# ATxmega128A1U device description
Architecture: AVR8_XMEGA; Family: AVR XMEGA
Registers are 8-bit, access not given, no defined reset value unless marked. A register's access mark holds for its fields unless they carry their own. Offsets are from the block's base; [hi:lo] are bit positions; lines under a group give offsets from that group; {n}, {i} and the like mark numbered series; 'fields as' and 'values as' point back to an identical list.

## USB_EP_TABLE — USB Endpoint Table
{0x0+0x10*i} EP{i}OUT group (i=0..15) — Endpoint {i}
  0x00 STATUS — Endpoint Status
    [7] STALLF — Endpoint Stall Flag
    [7] CRC — CRC Error Flag
    [6] UNF — Underflow Enpoint FLag
    [6] OVF — Overflow Enpoint Flag for Output Endpoints
    [5] TRNCOMPL0 — Transaction Complete 0 Flag
    [4] TRNCOMPL1 — Transaction Complete 1 Flag
    [4] SETUP — SETUP Transaction Complete Flag
    [3] BANK — Bank Select
    [2] BUSNACK1 — Data Buffer 1 Not Acknowledge
    [1] BUSNACK0 — Data Buffer 0 Not Acknowledge
    [0] TOGGLE — Data Toggle
  0x01 CTRL — Endpoint Control
    [7:6] TYPE — Endpoint Type
      0=DISABLE (Endpoint Disabled); 1=CONTROL; 2=BULK (Bulk/Interrupt); 3=ISOCHRONOUS
    [5] MULTIPKT — Multi Packet Transfer Enable
    [4] PINGPONG — Ping-Pong Enable
    [3] INTDSBL — Interrupt Disable
    [2] STALL — Data Stall
    [2:0] BUFSIZE — Data Buffer Size
      0=8 bytes buffer size; 1=16 bytes buffer size; 2=32 bytes buffer size; 3=64 bytes buffer size; 4=128 bytes buffer size; 5=256 bytes buffer size; 6=512 bytes buffer size; 7=1023 bytes buffer size
  0x02 CNT 16-bit — USB Endpoint Counter
    [15] ZLP — Zero Length Packet
  0x04 DATAPTR 16-bit — Data Pointer
  0x06 AUXDATA 16-bit — Auxiliary Data
{0x8+0x10*i} EP{i}IN group (i=0..15) — Endpoint {i}
  0x00 STATUS — Endpoint Status
    fields as EP0OUT.STATUS
  0x01 CTRL — Endpoint Control
    fields as EP0OUT.CTRL
  0x02 CNT 16-bit — USB Endpoint Counter
    [15] ZLP — Zero Length Packet
  0x04 DATAPTR 16-bit — Data Pointer
  0x06 AUXDATA 16-bit — Auxiliary Data
0x110 FRAMENUML — Frame Number Low Byte
0x111 FRAMENUMH — Frame Number High Byte

## PORT — I/O Ports
Instances: PORTA 0x0600, PORTB 0x0620, PORTC 0x0640, PORTD 0x0660, PORTE 0x0680, PORTF 0x06A0, PORTH 0x06E0, PORTJ 0x0700, PORTK 0x0720, PORTQ 0x07C0, PORTR 0x07E0
0x00 DIR — I/O Port Data Direction
0x01 DIRSET — I/O Port Data Direction Set
0x02 DIRCLR — I/O Port Data Direction Clear
0x03 DIRTGL — I/O Port Data Direction Toggle
0x04 OUT — I/O Port Output
0x05 OUTSET — I/O Port Output Set
0x06 OUTCLR — I/O Port Output Clear
0x07 OUTTGL — I/O Port Output Toggle
0x08 IN — I/O port Input
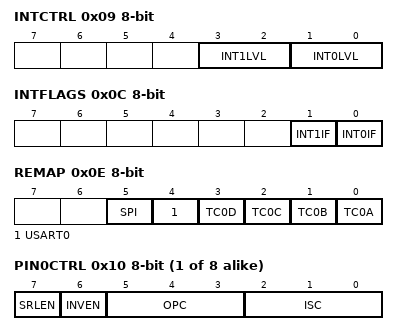
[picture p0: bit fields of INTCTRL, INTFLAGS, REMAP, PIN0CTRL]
0x09 INTCTRL — Interrupt Control Register
  [3:2] INT1LVL — Port Interrupt 1 Level
    0=OFF (Interrupt Disabled); 1=LO (Low Level); 2=MED (Medium Level); 3=HI (High Level)
  [1:0] INT0LVL — Port Interrupt 0 Level
    values as INT1LVL
0x0A INT0MASK — Port Interrupt 0 Mask
0x0B INT1MASK — Port Interrupt 1 Mask
0x0C INTFLAGS — Interrupt Flag Register
  [1] INT1IF — Port Interrupt 1 Flag
  [0] INT0IF — Port Interrupt 0 Flag
0x0E REMAP — I/O Port Pin Remap Register
  [5] SPI
  [4] USART0
  [3] TC0D — Timer/Counter 0 Output Compare D
  [2] TC0C — Timer/Counter 0 Output Compare C
  [1] TC0B — Timer/Counter 0 Output Compare B
  [0] TC0A — Timer/Counter 0 Output Compare A
{0x10+i} PIN{i}CTRL (i=0..7) — Pin {i} Control Register
  [7] SRLEN — Slew Rate Enable
  [6] INVEN — Inverted I/O Enable
  [5:3] OPC — Output/Pull Configuration
    0=TOTEM (Totempole); 1=BUSKEEPER (Totempole w/ Bus keeper on Input and Output); 2=PULLDOWN (Totempole w/ Pull-down on Input); 3=PULLUP (Totempole w/ Pull-up on Input); 4=WIREDOR; 5=WIREDAND; 6=WIREDORPULL (Wired OR w/ Pull-down); 7=WIREDANDPULL (Wired AND w/ Pull-up)
  [2:0] ISC — Input/Sense Configuration
    0=BOTHEDGES (Sense Both Edges); 1=RISING (Sense Rising Edge); 2=FALLING (Sense Falling Edge); 3=LEVEL (Sense Level (Transparent For Events)); 7=INPUT_DISABLE (Disable Digital Input Buffer)

## TC2 — 16-bit Timer/Counter type 2
Instances: TCC2 0x800, TCD2 0x900, TCE2 0xA00, TCF2 0xB00
0x00 CTRLA — Control Register A
  [3:0] CLKSEL — Clock Selection
    0=OFF (Timer Off); 1=DIV1 (System Clock); 2=DIV2 (System Clock / 2); 3=DIV4 (System Clock / 4); 4=DIV8 (System Clock / 8); 5=DIV64 (System Clock / 64); 6=DIV256 (System Clock / 256); 7=DIV1024 (System Clock / 1024); {v}=EVCH{v-8} (Event Channel {v-8}) (v=8..15)
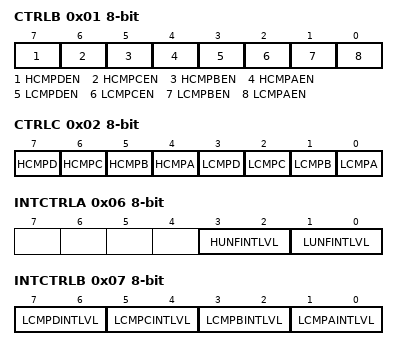
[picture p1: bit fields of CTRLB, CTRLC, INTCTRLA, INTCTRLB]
0x01 CTRLB — Control Register B
  [7] HCMPDEN — High Byte Compare D Enable
  [6] HCMPCEN — High Byte Compare C Enable
  [5] HCMPBEN — High Byte Compare B Enable
  [4] HCMPAEN — High Byte Compare A Enable
  [3] LCMPDEN — Low Byte Compare D Enable
  [2] LCMPCEN — Low Byte Compare C Enable
  [1] LCMPBEN — Low Byte Compare B Enable
  [0] LCMPAEN — Low Byte Compare A Enable
0x02 CTRLC — Control register C
  [7] HCMPD — High Byte Compare D Output Value
  [6] HCMPC — High Byte Compare C Output Value
  [5] HCMPB — High Byte Compare B Output Value
  [4] HCMPA — High Byte Compare A Output Value
  [3] LCMPD — Low Byte Compare D Output Value
  [2] LCMPC — Low Byte Compare C Output Value
  [1] LCMPB — Low Byte Compare B Output Value
  [0] LCMPA — Low Byte Compare A Output Value
0x04 CTRLE — Control Register E
  [1:0] BYTEM — Byte Mode
    0=NORMAL (16-bit mode); 1=BYTEMODE (Timer/Counter operating in byte mode only (TC2)); 2=SPLITMODE (Timer/Counter split into two 8-bit Counters)
0x06 INTCTRLA — Interrupt Control Register A
  [3:2] HUNFINTLVL — High Byte Underflow Interrupt Level
    0=OFF (Interrupt Disabled); 1=LO (Low Level); 2=MED (Medium Level); 3=HI (High Level)
  [1:0] LUNFINTLVL — Low Byte Underflow interrupt level
    values as HUNFINTLVL
0x07 INTCTRLB — Interrupt Control Register B
  [all] fields
    values as INTCTRLA.HUNFINTLVL
  [7:6] LCMPDINTLVL — Low Byte Compare D Interrupt Level
  [5:4] LCMPCINTLVL — Low Byte Compare C Interrupt Level
  [3:2] LCMPBINTLVL — Low Byte Compare B Interrupt Level
  [1:0] LCMPAINTLVL — Low Byte Compare A Interrupt Level
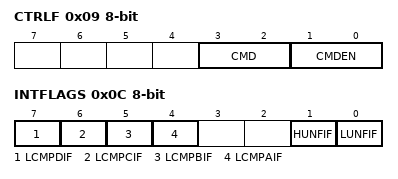
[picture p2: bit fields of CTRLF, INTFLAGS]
0x09 CTRLF — Control Register F
  [3:2] CMD — Command
    0=NONE (No Command); 2=RESTART (Force Restart); 3=RESET (Force Hard Reset)
  [1:0] CMDEN — Command Enable
    1=LOW (Low Byte Timer/Counter); 2=HIGH (High Byte Timer/Counter); 3=BOTH (Both Low Byte and High Byte Timer/Counters)
0x0C INTFLAGS — Interrupt Flag Register
  [7] LCMPDIF — Low Byte Compare D Interrupt Flag
  [6] LCMPCIF — Low Byte Compare C Interrupt Flag
  [5] LCMPBIF — Low Byte Compare B Interrupt Flag
  [4] LCMPAIF — Low Byte Compare A Interrupt Flag
  [1] HUNFIF — High Byte Underflow Interrupt Flag
  [0] LUNFIF — Low Byte Underflow Interrupt Flag
0x20 LCNT — Low Byte Count
0x21 HCNT — High Byte Count
0x26 LPER — Low Byte Period
0x27 HPER — High Byte Period
0x28 LCMPA — Low Byte Compare A
0x29 HCMPA — High Byte Compare A
0x2A LCMPB — Low Byte Compare B
0x2B HCMPB — High Byte Compare B
0x2C LCMPC — Low Byte Compare C
0x2D HCMPC — High Byte Compare C
0x2E LCMPD — Low Byte Compare D
0x2F HCMPD — High Byte Compare D
